# ATSAMS70N21 register map
Vendor: Microchip Technology; File version: 0
CPU: CM7 r1p1, little endian, no MPU, no FPU, 0x3 interrupt priority bits, 0x0 interrupts
Registers are 32-bit, read-write, reset 0x0 unless marked. A register's access mark holds for its fields unless they carry their own. Offsets are from the block's base; [hi:lo] are bit positions; {n}, {i} and the like mark numbered series.

## WDT — Watchdog Timer
Base 0x400E1850; register names take the prefix WDT_
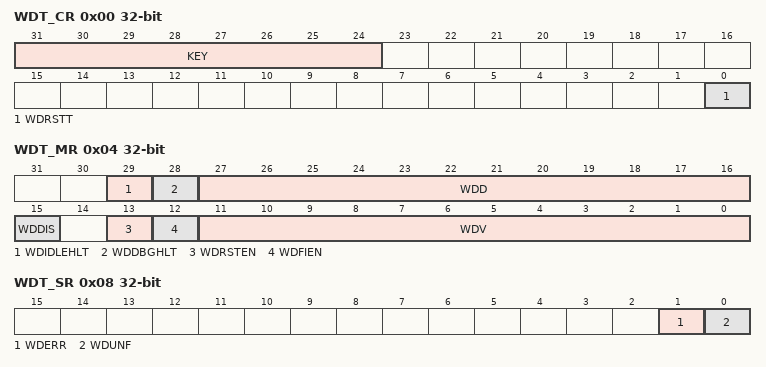
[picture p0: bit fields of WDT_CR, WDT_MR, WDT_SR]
0x00 WDT_CR wo — Control Register
  [31:24] KEY — Password
    165=PASSWD (Writing any other value in this field aborts the write operation.)
  [0] WDRSTT — Watchdog Restart
0x04 WDT_MR — Mode Register
  [29] WDIDLEHLT — Watchdog Idle Halt
  [28] WDDBGHLT — Watchdog Debug Halt
  [27:16] WDD — Watchdog Delta Value
  [15] WDDIS — Watchdog Disable
  [13] WDRSTEN — Watchdog Reset Enable
  [12] WDFIEN — Watchdog Fault Interrupt Enable
  [11:0] WDV — Watchdog Counter Value
0x08 WDT_SR ro — Status Register
  [1] WDERR — Watchdog Error (cleared on read)
  [0] WDUNF — Watchdog Underflow (cleared on read)

## XDMAC — Extensible DMA Controller
Base 0x40078000; register names take the prefix XDMAC_
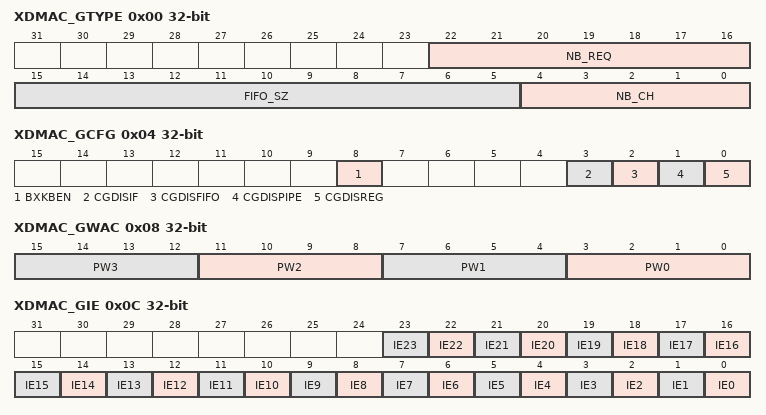
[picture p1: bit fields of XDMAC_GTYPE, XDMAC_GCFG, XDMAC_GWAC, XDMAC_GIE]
0x00 XDMAC_GTYPE ro — Global Type Register
  [22:16] NB_REQ — Number of Peripheral Requests Minus One
  [15:5] FIFO_SZ — Number of Bytes
  [4:0] NB_CH — Number of Channels Minus One
0x04 XDMAC_GCFG — Global Configuration Register
  [8] BXKBEN — Boundary X Kilobyte Enable
  [3] CGDISIF — Bus Interface Clock Gating Disable
  [2] CGDISFIFO — FIFO Clock Gating Disable
  [1] CGDISPIPE — Pipeline Clock Gating Disable
  [0] CGDISREG — Configuration Registers Clock Gating Disable
0x08 XDMAC_GWAC — Global Weighted Arbiter Configuration Register
  [4n+3:4n] PW{n} (n=0..3) — Pool Weight {n}
0x0C XDMAC_GIE wo — Global Interrupt Enable Register
  [n] IE{n} (n=0..23) — XDMAC Channel {n} Interrupt Enable Bit
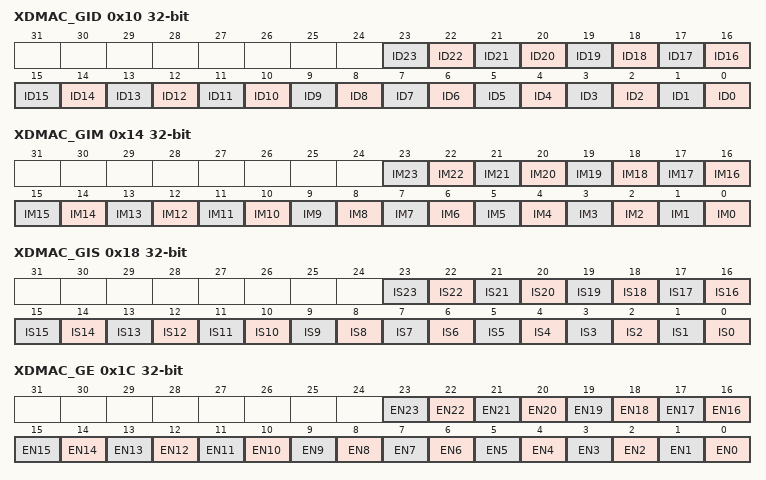
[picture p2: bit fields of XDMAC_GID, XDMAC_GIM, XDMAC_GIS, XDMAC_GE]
0x10 XDMAC_GID wo — Global Interrupt Disable Register
  [n] ID{n} (n=0..23) — XDMAC Channel {n} Interrupt Disable Bit
0x14 XDMAC_GIM ro — Global Interrupt Mask Register
  [n] IM{n} (n=0..23) — XDMAC Channel {n} Interrupt Mask Bit
0x18 XDMAC_GIS ro — Global Interrupt Status Register
  [n] IS{n} (n=0..23) — XDMAC Channel {n} Interrupt Status Bit
0x1C XDMAC_GE wo — Global Channel Enable Register
  [n] EN{n} (n=0..23) — XDMAC Channel {n} Enable Bit
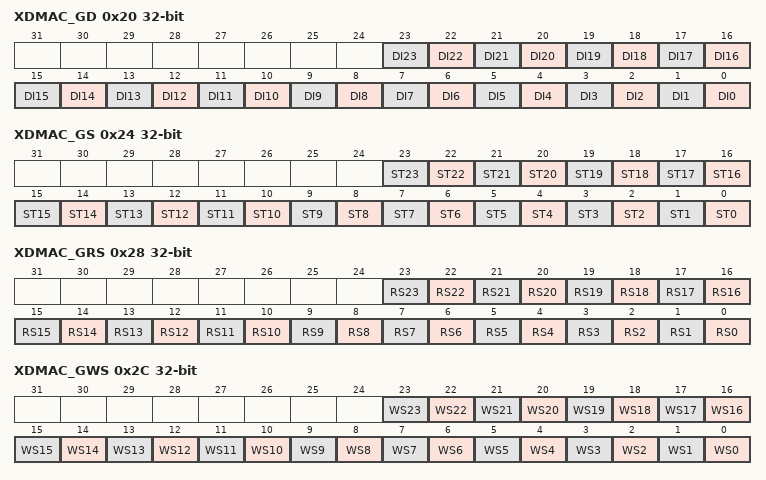
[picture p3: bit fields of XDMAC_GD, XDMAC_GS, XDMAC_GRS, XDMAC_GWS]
0x20 XDMAC_GD wo — Global Channel Disable Register
  [n] DI{n} (n=0..23) — XDMAC Channel {n} Disable Bit
0x24 XDMAC_GS ro — Global Channel Status Register
  [n] ST{n} (n=0..23) — XDMAC Channel {n} Status Bit
0x28 XDMAC_GRS — Global Channel Read Suspend Register
  [n] RS{n} (n=0..23) — XDMAC Channel {n} Read Suspend Bit
0x2C XDMAC_GWS — Global Channel Write Suspend Register
  [n] WS{n} (n=0..23) — XDMAC Channel {n} Write Suspend Bit
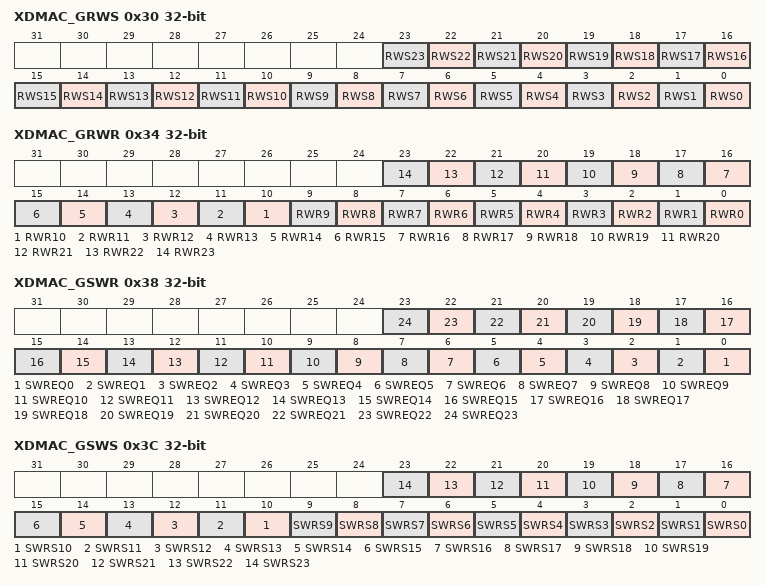
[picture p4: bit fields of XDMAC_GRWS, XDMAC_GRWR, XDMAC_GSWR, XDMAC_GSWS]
0x30 XDMAC_GRWS wo — Global Channel Read Write Suspend Register
  [n] RWS{n} (n=0..23) — XDMAC Channel {n} Read Write Suspend Bit
0x34 XDMAC_GRWR wo — Global Channel Read Write Resume Register
  [n] RWR{n} (n=0..23) — XDMAC Channel {n} Read Write Resume Bit
0x38 XDMAC_GSWR wo — Global Channel Software Request Register
  [n] SWREQ{n} (n=0..23) — XDMAC Channel {n} Software Request Bit
0x3C XDMAC_GSWS ro — Global Channel Software Request Status Register
  [n] SWRS{n} (n=0..23) — XDMAC Channel {n} Software Request Status Bit
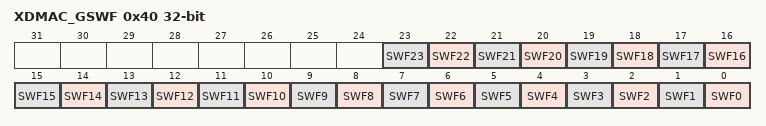
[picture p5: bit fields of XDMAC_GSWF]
0x40 XDMAC_GSWF wo — Global Channel Software Flush Request Register
  [n] SWF{n} (n=0..23) — XDMAC Channel {n} Software Flush Request Bit

## LOCKBIT
Base 0x00000000; register names take the prefix LOCKBIT_
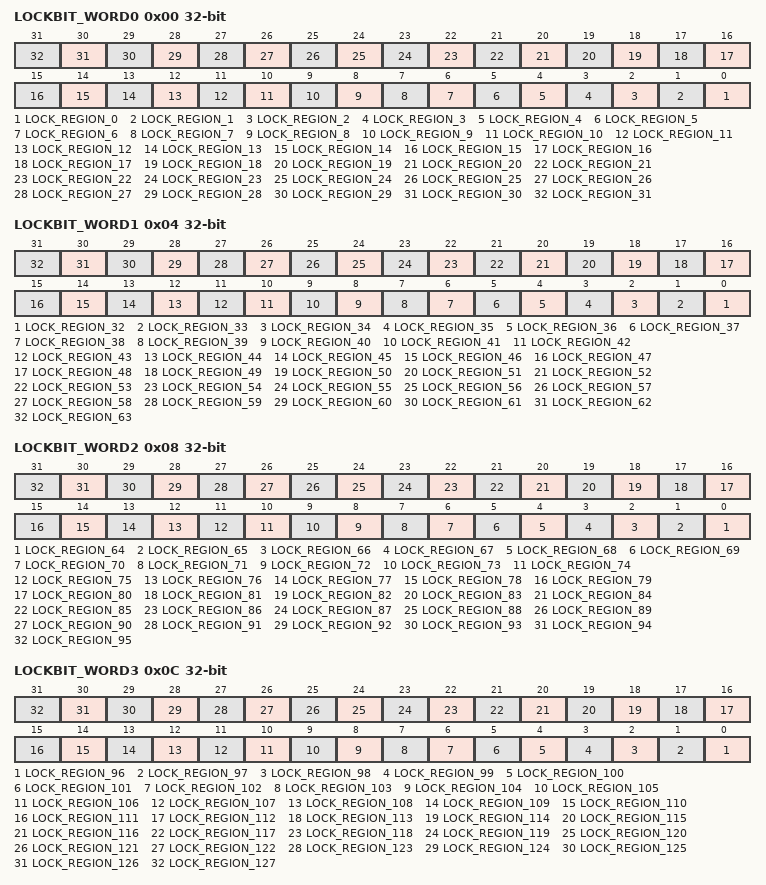
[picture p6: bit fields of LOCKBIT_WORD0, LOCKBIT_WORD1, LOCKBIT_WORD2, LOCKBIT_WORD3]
0x00 LOCKBIT_WORD0 — Lock Bits Word 0
  [n] LOCK_REGION_{n} (n=0..31)
0x04 LOCKBIT_WORD1 — Lock Bits Word 1
  [n-32] LOCK_REGION_{n} (n=32..63)
0x08 LOCKBIT_WORD2 — Lock Bits Word 2
  [n-64] LOCK_REGION_{n} (n=64..95)
0x0C LOCKBIT_WORD3 — Lock Bits Word 3
  [n-96] LOCK_REGION_{n} (n=96..127)

## SCnSCB — System control not in SCB
Base 0xE000E000; register names take the prefix SCnSCB_
0x04 ICTR ro — Interrupt Controller Type Register
  [3:0] INTLINESNUM — Total number of interrupt lines supported by an implementation, defined in groups of 32
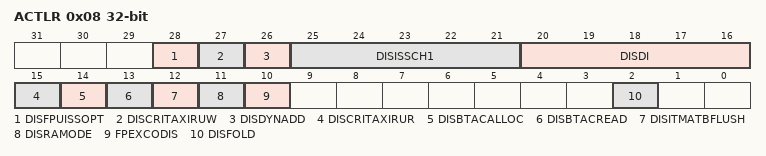
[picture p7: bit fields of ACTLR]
0x08 ACTLR — Auxiliary Control Register
  [28] DISFPUISSOPT — Disables dynamic allocation of ADD and SUB instructions
  [27] DISCRITAXIRUW — Disable critical AXI read-under-write
  [26] DISDYNADD — Disables dynamic allocation of ADD and SUB instructions
  [25:21] DISISSCH1
  [20:16] DISDI
  [15] DISCRITAXIRUR
  [14] DISBTACALLOC
  [13] DISBTACREAD
  [12] DISITMATBFLUSH — Disables ITM and DWT ATB flush
  [11] DISRAMODE — Disables dynamic read allocate mode for Write-Back Write-Allocate memory regions
  [10] FPEXCODIS — Disables FPU exception outputs
  [2] DISFOLD — Disables folding of IT instructions
